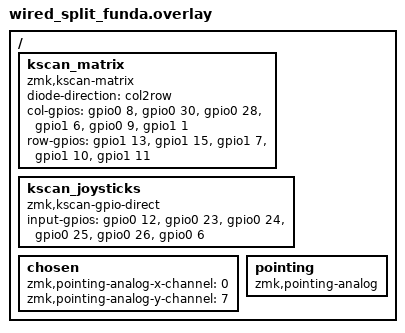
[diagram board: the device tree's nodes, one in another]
/*
 * Overlay para la Funda Teclado 6x5 con 2 Joysticks
 * Definiciones de Hardware
 */

#include <dt-bindings/zmk/matrix_transform.h> // Necesario para kscan_matrix

/ {
    // --- Definición de Pines de Matriz (6x5 = 30 teclas) ---
    kscan_matrix: kscan_matrix {
        compatible = "zmk,kscan-matrix";
        diode-direction = "col2row"; //
        col-gpios
            = <&gpio0 8 GPIO_ACTIVE_HIGH>  // Col 0 (P0.08)
            , <&gpio0 30 GPIO_ACTIVE_HIGH>  // Col 1 (P0.30)
            , <&gpio0 28 GPIO_ACTIVE_HIGH>  // Col 2 (P0.28)
            , <&gpio1 6 GPIO_ACTIVE_HIGH>  // Col 3 (P1.06)
            , <&gpio0 9 GPIO_ACTIVE_HIGH>  // Col 4 (P0.09)
            , <&gpio1 1 GPIO_ACTIVE_HIGH>  // Col 5 (P1.01)
            ; //
        row-gpios
            = <&gpio1 13 (GPIO_ACTIVE_HIGH | GPIO_PULL_DOWN)> // Fila 0 (P1.13)
            , <&gpio1 15 (GPIO_ACTIVE_HIGH | GPIO_PULL_DOWN)> // Fila 1 (P1.15)
            , <&gpio1 7 (GPIO_ACTIVE_HIGH | GPIO_PULL_DOWN)> // Fila 2 (P1.07)
            , <&gpio1 10 (GPIO_ACTIVE_HIGH | GPIO_PULL_DOWN)> // Fila 3 (P1.10)
            , <&gpio1 11 (GPIO_ACTIVE_HIGH | GPIO_PULL_DOWN)> // Fila 4 (P1.11)
            ; //
    };

    // --- Definición de Pines de Joysticks (Digitales) ---
    kscan_joysticks: kscan_joysticks {
        compatible = "zmk,kscan-gpio-direct"; //
        input-gpios
            // Joystick 1 (Digital - Modificadores)
            = <&gpio0 12 (GPIO_ACTIVE_HIGH | GPIO_PULL_DOWN)>  // Joy1 Arriba (P0.12)
            , <&gpio0 23 (GPIO_ACTIVE_HIGH | GPIO_PULL_DOWN)>  // Joy1 Abajo (P0.23)
            , <&gpio0 24 (GPIO_ACTIVE_HIGH | GPIO_PULL_DOWN)>  // Joy1 Izquierda (P0.24)
            , <&gpio0 25 (GPIO_ACTIVE_HIGH | GPIO_PULL_DOWN)>  // Joy1 Derecha (P0.25)
            , <&gpio0 26 (GPIO_ACTIVE_HIGH | GPIO_PULL_DOWN)>  // Joy1 Botón (P0.26)

            // Joystick 2 (Botón del Mouse)
            , <&gpio0 6 (GPIO_ACTIVE_HIGH | GPIO_PULL_DOWN)>  // Joy2 Botón (P0.06)
            ; //
    };

    // --- Definición de Ejes de Joystick 2 (Analógico - Mouse) ---
    chosen {
        zmk,pointing-analog-x-channel = <0>; // P0.02 (D20) es ADC Canal 0
        zmk,pointing-analog-y-channel = <7>; // P0.31 (D21) es ADC Canal 7
    }; //

    pointing: pointing {
        compatible = "zmk,pointing-analog";
    }; //
};
